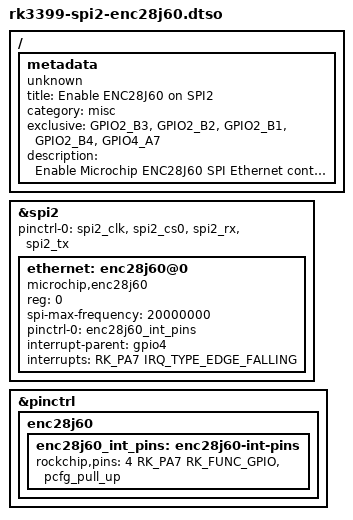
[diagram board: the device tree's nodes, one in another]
/dts-v1/;
/plugin/;

#include <dt-bindings/gpio/gpio.h>
#include <dt-bindings/pinctrl/rockchip.h>
#include <dt-bindings/interrupt-controller/irq.h>

/ {
	metadata {
		title = "Enable ENC28J60 on SPI2";
		compatible = "unknown";
		category = "misc";
		exclusive = "GPIO2_B3", "GPIO2_B2", "GPIO2_B1", "GPIO2_B4", "GPIO4_A7";
		description = "Enable Microchip ENC28J60 SPI Ethernet controller on SPI2.
INT=40";
	};
};

&spi2 {
	status = "okay";
	#address-cells = <1>;
	#size-cells = <0>;
	pinctrl-names = "default";
	pinctrl-0 = <&spi2_clk &spi2_cs0 &spi2_rx &spi2_tx>;

	ethernet: enc28j60@0 {
		compatible = "microchip,enc28j60";
		reg = <0>;
		spi-max-frequency = <20000000>;

		pinctrl-names = "default";
		pinctrl-0 = <&enc28j60_int_pins>;

		interrupt-parent = <&gpio4>;
		interrupts = <RK_PA7 IRQ_TYPE_EDGE_FALLING>;
	};
};

&pinctrl {
	enc28j60 {
		enc28j60_int_pins: enc28j60-int-pins {
			rockchip,pins = <4 RK_PA7 RK_FUNC_GPIO &pcfg_pull_up>;
		};
	};
};
